# STM32F423 register map
File version: 1.2
CPU: CM4 r0p1, little endian, MPU, FPU, 4 interrupt priority bits
Registers are 32-bit, read-write, reset 0x0 unless marked. A register's access mark holds for its fields unless they carry their own. Offsets are from the block's base; [hi:lo] are bit positions; {n}, {i} and the like mark numbered series.

## RCC — Reset and clock control
Base 0x40023800
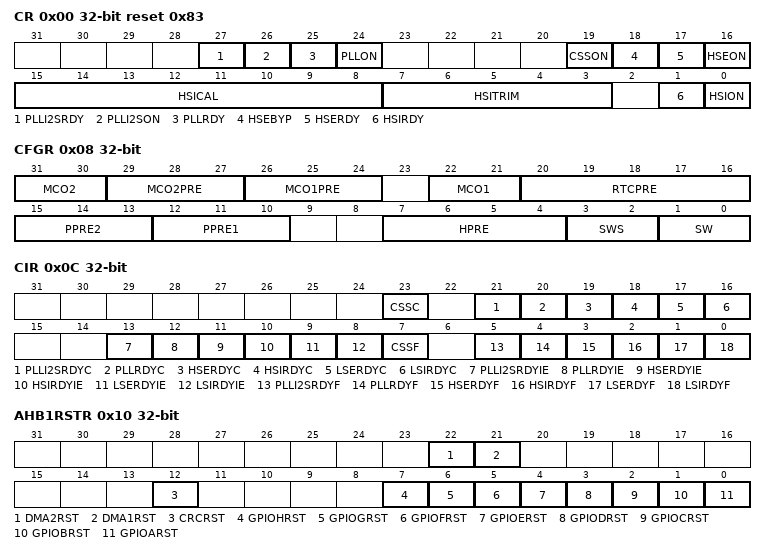
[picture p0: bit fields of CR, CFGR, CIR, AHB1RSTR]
0x00 CR reset 0x83 — clock control register
  [27] PLLI2SRDY, [26] PLLI2SON, [25] PLLRDY, [24] PLLON, [19] CSSON, [18] HSEBYP, [17] HSERDY, [16] HSEON, [15:8] HSICAL, [7:3] HSITRIM, [1] HSIRDY, [0] HSION
0x04 PLLCFGR reset 0x24003010 — PLL configuration register
  [30:28] PLLR, [27:24] PLLQ, [22] PLLSRC, [22] PLLSRC_HSE, [17:16] PLLP, [14:6] PLLN, [5:0] PLLM
0x08 CFGR access not given — clock configuration register
  [31:30] MCO2 rw, [29:27] MCO2PRE rw, [26:24] MCO1PRE rw, [22:21] MCO1 rw, [20:16] RTCPRE rw, [15:13] PPRE2 rw, [12:10] PPRE1 rw, [7:4] HPRE rw, [3:2] SWS, [1:0] SW
0x0C CIR access per field — clock interrupt register
  [23] CSSC wo, [21] PLLI2SRDYC wo, [20] PLLRDYC wo, [19] HSERDYC wo, [18] HSIRDYC wo, [17] LSERDYC wo, [16] LSIRDYC wo, [13] PLLI2SRDYIE rw, [12] PLLRDYIE rw, [11] HSERDYIE rw, [10] HSIRDYIE rw, [9] LSERDYIE rw, [8] LSIRDYIE rw, [7] CSSF ro, [5] PLLI2SRDYF ro, [4] PLLRDYF ro, [3] HSERDYF ro, [2] HSIRDYF ro, [1] LSERDYF ro, [0] LSIRDYF ro
0x10 AHB1RSTR — AHB1 peripheral reset register
  [22] DMA2RST, [21] DMA1RST, [12] CRCRST, [7] GPIOHRST, [6] GPIOGRST, [5] GPIOFRST, [4] GPIOERST, [3] GPIODRST, [2] GPIOCRST, [1] GPIOBRST, [0] GPIOARST
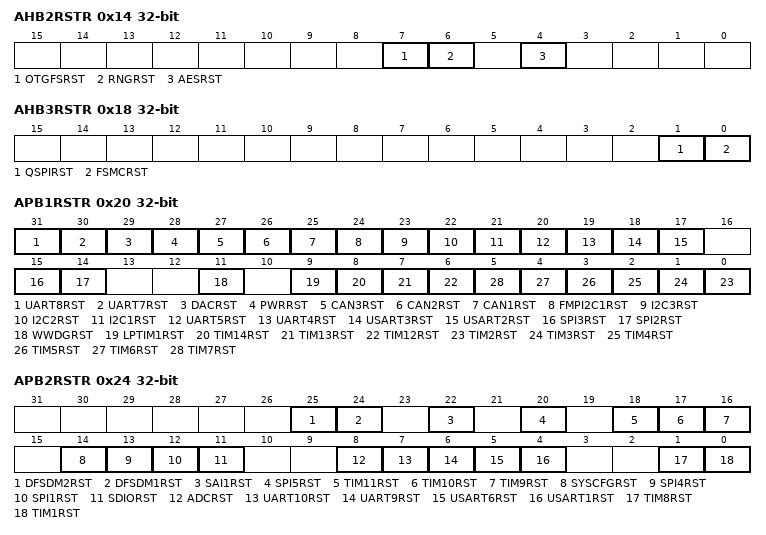
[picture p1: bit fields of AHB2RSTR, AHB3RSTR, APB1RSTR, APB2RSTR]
0x14 AHB2RSTR — AHB2 peripheral reset register
  [7] OTGFSRST, [6] RNGRST, [4] AESRST
0x18 AHB3RSTR — peripheral reset register
  [1] QSPIRST, [0] FSMCRST
0x20 APB1RSTR — APB1 peripheral reset register
  [31] UART8RST, [30] UART7RST, [29] DACRST, [28] PWRRST, [27] CAN3RST, [26] CAN2RST, [25] CAN1RST, [24] FMPI2C1RST, [23] I2C3RST, [22] I2C2RST, [21] I2C1RST, [20] UART5RST, [19] UART4RST, [18] USART3RST, [17] USART2RST, [15] SPI3RST, [14] SPI2RST, [11] WWDGRST, [9] LPTIM1RST, [8] TIM14RST, [7] TIM13RST, [6] TIM12RST, [n-2] TIM{n}RST (n=2..7)
0x24 APB2RSTR — APB2 peripheral reset register
  [25] DFSDM2RST, [24] DFSDM1RST, [22] SAI1RST, [20] SPI5RST, [18] TIM11RST, [17] TIM10RST, [16] TIM9RST, [14] SYSCFGRST, [13] SPI4RST, [12] SPI1RST, [11] SDIORST, [8] ADCRST, [7] UART10RST, [6] UART9RST, [5] USART6RST, [4] USART1RST, [1] TIM8RST, [0] TIM1RST
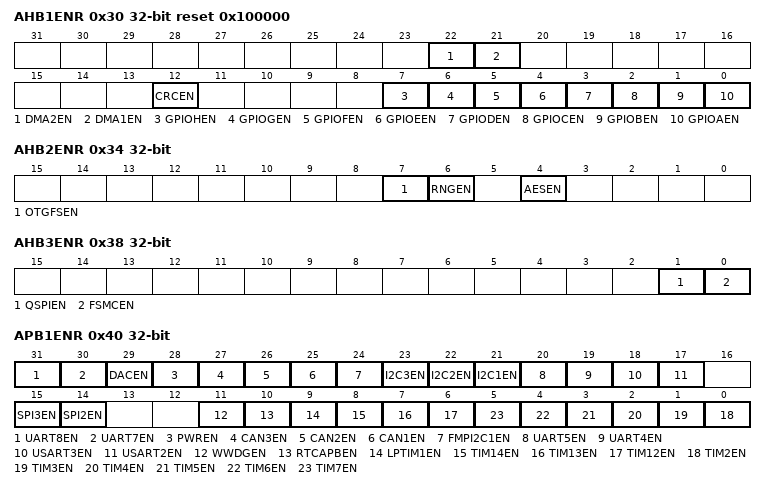
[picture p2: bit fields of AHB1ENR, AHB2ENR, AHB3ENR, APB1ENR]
0x30 AHB1ENR reset 0x100000 — AHB1 peripheral clock register
  [22] DMA2EN, [21] DMA1EN, [12] CRCEN, [7] GPIOHEN, [6] GPIOGEN, [5] GPIOFEN, [4] GPIOEEN, [3] GPIODEN, [2] GPIOCEN, [1] GPIOBEN, [0] GPIOAEN
0x34 AHB2ENR — AHB2 peripheral clock enable register
  [7] OTGFSEN, [6] RNGEN, [4] AESEN
0x38 AHB3ENR — AHB3 peripheral clock enable register
  [1] QSPIEN, [0] FSMCEN
0x40 APB1ENR — APB1 peripheral clock enable register
  [31] UART8EN, [30] UART7EN, [29] DACEN, [28] PWREN, [27] CAN3EN, [26] CAN2EN, [25] CAN1EN, [24] FMPI2C1EN, [23] I2C3EN, [22] I2C2EN, [21] I2C1EN, [20] UART5EN, [19] UART4EN, [18] USART3EN, [17] USART2EN, [15] SPI3EN, [14] SPI2EN, [11] WWDGEN, [10] RTCAPBEN, [9] LPTIM1EN, [8] TIM14EN, [7] TIM13EN, [6] TIM12EN, [n-2] TIM{n}EN (n=2..7)
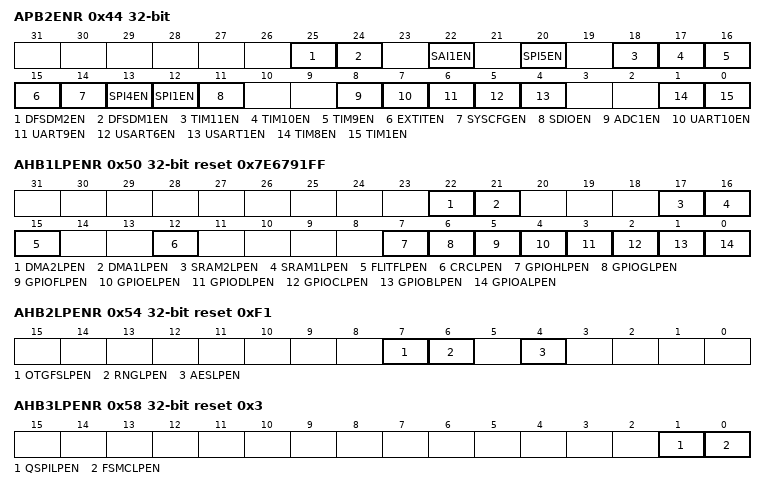
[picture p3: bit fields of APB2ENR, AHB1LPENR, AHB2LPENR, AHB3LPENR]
0x44 APB2ENR — APB2 peripheral clock enable register
  [25] DFSDM2EN, [24] DFSDM1EN, [22] SAI1EN, [20] SPI5EN, [18] TIM11EN, [17] TIM10EN, [16] TIM9EN, [15] EXTITEN, [14] SYSCFGEN, [13] SPI4EN, [12] SPI1EN, [11] SDIOEN, [8] ADC1EN, [7] UART10EN, [6] UART9EN, [5] USART6EN, [4] USART1EN, [1] TIM8EN, [0] TIM1EN
0x50 AHB1LPENR reset 0x7E6791FF — AHB1 peripheral clock enable in low power mode register
  [22] DMA2LPEN, [21] DMA1LPEN, [17] SRAM2LPEN, [16] SRAM1LPEN, [15] FLITFLPEN, [12] CRCLPEN, [7] GPIOHLPEN, [6] GPIOGLPEN, [5] GPIOFLPEN, [4] GPIOELPEN, [3] GPIODLPEN, [2] GPIOCLPEN, [1] GPIOBLPEN, [0] GPIOALPEN
0x54 AHB2LPENR reset 0xF1 — AHB2 peripheral clock enable in low power mode register
  [7] OTGFSLPEN, [6] RNGLPEN, [4] AESLPEN
0x58 AHB3LPENR reset 0x3 — AHB3 peripheral clock enable in low power mode register
  [1] QSPILPEN, [0] FSMCLPEN
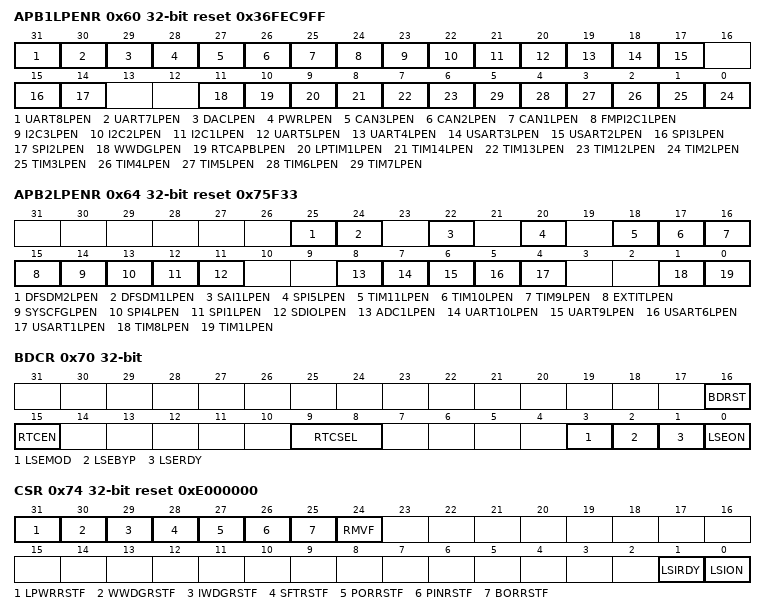
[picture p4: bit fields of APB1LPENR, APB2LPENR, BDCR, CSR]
0x60 APB1LPENR reset 0x36FEC9FF — APB1 peripheral clock enable in low power mode register
  [31] UART8LPEN, [30] UART7LPEN, [29] DACLPEN, [28] PWRLPEN, [27] CAN3LPEN, [26] CAN2LPEN, [25] CAN1LPEN, [24] FMPI2C1LPEN, [23] I2C3LPEN, [22] I2C2LPEN, [21] I2C1LPEN, [20] UART5LPEN, [19] UART4LPEN, [18] USART3LPEN, [17] USART2LPEN, [15] SPI3LPEN, [14] SPI2LPEN, [11] WWDGLPEN, [10] RTCAPBLPEN, [9] LPTIM1LPEN, [8] TIM14LPEN, [7] TIM13LPEN, [6] TIM12LPEN, [n-2] TIM{n}LPEN (n=2..7)
0x64 APB2LPENR reset 0x75F33 — APB2 peripheral clock enabled in low power mode register
  [25] DFSDM2LPEN, [24] DFSDM1LPEN, [22] SAI1LPEN, [20] SPI5LPEN, [18] TIM11LPEN, [17] TIM10LPEN, [16] TIM9LPEN, [15] EXTITLPEN, [14] SYSCFGLPEN, [13] SPI4LPEN, [12] SPI1LPEN, [11] SDIOLPEN, [8] ADC1LPEN, [7] UART10LPEN, [6] UART9LPEN, [5] USART6LPEN, [4] USART1LPEN, [1] TIM8LPEN, [0] TIM1LPEN
0x70 BDCR access not given — Backup domain control register
  [16] BDRST rw, [15] RTCEN rw, [9:8] RTCSEL, [3] LSEMOD rw, [2] LSEBYP rw, [1] LSERDY ro, [0] LSEON rw
0x74 CSR access not given reset 0xE000000 — clock control & status register
  [31] LPWRRSTF rw, [30] WWDGRSTF rw, [29] IWDGRSTF, [28] SFTRSTF rw, [27] PORRSTF rw, [26] PINRSTF, [25] BORRSTF rw, [24] RMVF rw, [1] LSIRDY ro, [0] LSION rw
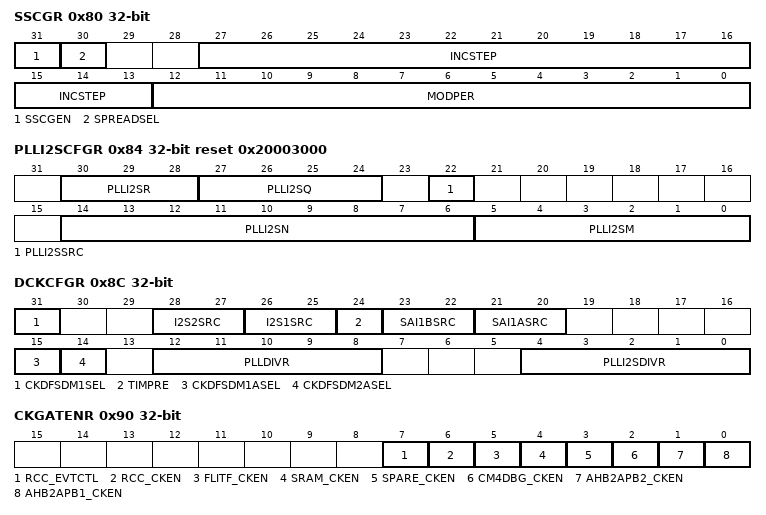
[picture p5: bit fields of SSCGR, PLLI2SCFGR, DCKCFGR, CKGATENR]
0x80 SSCGR — spread spectrum clock generation register
  [31] SSCGEN, [30] SPREADSEL, [27:13] INCSTEP, [12:0] MODPER
0x84 PLLI2SCFGR reset 0x20003000 — PLLI2S configuration register
  [30:28] PLLI2SR, [27:24] PLLI2SQ, [22] PLLI2SSRC, [14:6] PLLI2SN, [5:0] PLLI2SM
0x8C DCKCFGR — Dedicated Clocks Configuration Register
  [31] CKDFSDM1SEL, [28:27] I2S2SRC, [26:25] I2S1SRC, [24] TIMPRE, [23:22] SAI1BSRC, [21:20] SAI1ASRC, [15] CKDFSDM1ASEL, [14] CKDFSDM2ASEL, [12:8] PLLDIVR, [4:0] PLLI2SDIVR
0x90 CKGATENR — RCC clocks gated enable register
  [7] RCC_EVTCTL, [6] RCC_CKEN, [5] FLITF_CKEN, [4] SRAM_CKEN, [3] SPARE_CKEN, [2] CM4DBG_CKEN, [1] AHB2APB2_CKEN, [0] AHB2APB1_CKEN
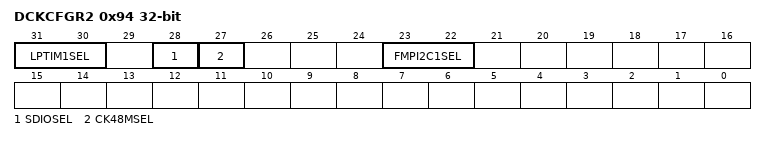
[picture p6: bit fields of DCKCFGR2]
0x94 DCKCFGR2 — Dedicated Clocks Configuration Register
  [31:30] LPTIM1SEL, [28] SDIOSEL, [27] CK48MSEL, [23:22] FMPI2C1SEL
